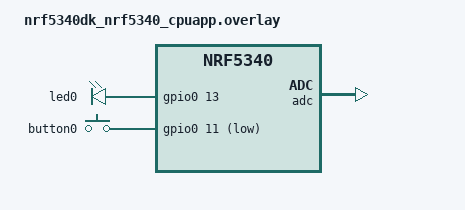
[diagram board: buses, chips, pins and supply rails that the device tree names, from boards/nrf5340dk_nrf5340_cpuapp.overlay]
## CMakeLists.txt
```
cmake_minimum_required(VERSION 3.13.1)
find_package(Zephyr REQUIRED HINTS $ENV{ZEPHYR_BASE})
project(fw_challenge)

target_sources(app PRIVATE
    src/main.c
    src/adc_sampler.c
    src/status_led.c
    src/buttons.c
    src/ble.c
)
target_include_directories(app PRIVATE include)
```

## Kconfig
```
menu "FW Challenge Options"

config APP_SAMPLE_INTERVAL_MS
    int "Sample interval (ms)"
    default 0
    help
      If non-zero, this Kconfig value takes precedence over the devicetree
      sample_interval_ms property. Use 0 to indicate "use devicetree/default".

config APP_ENABLE_BLE
    bool "Enable BLE support (build-time)"
    default y
    help
      If enabled, Bluetooth stack is built into the firmware. You can also
      disable Bluetooth with the overlay file 'overlay-no-ble.conf'.

config APP_LED_ACTIVE_LOW
    bool "Status LED active low"
    default n
    help
      Whether the status LED is active low. Defaults to n.

endmenu
```

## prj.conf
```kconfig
# Core
CONFIG_LOG=y
CONFIG_LOG_DEFAULT_LEVEL=3
CONFIG_SETTINGS=y
CONFIG_SETTINGS_NVS=y
CONFIG_NVS=y
CONFIG_FLASH=y
CONFIG_SYSTEM_WORKQUEUE=y
CONFIG_GPIO=y
CONFIG_ADC=y
CONFIG_PM=y
CONFIG_DEVICE_POWER_MANAGEMENT=y
CONFIG_MAIN_STACK_SIZE=2048

# Bluetooth (can be turned off with overlay-no-ble.conf)
CONFIG_BT=y
CONFIG_BT_PERIPHERAL=y
CONFIG_BT_DEVICE_NAME="FW-CHALLENGE"
CONFIG_BT_GATT_SERVICE_CHANGED=n
CONFIG_BT_MAX_CONN=1

# Enable ztest
CONFIG_ZTEST=y
```

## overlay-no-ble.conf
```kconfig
# Disable Bluetooth for builds that don't need it
CONFIG_BT=n
CONFIG_BT_PERIPHERAL=n
```

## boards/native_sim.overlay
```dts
/ {
    aliases {
        led-status = &led0;
        btn-user = &button0;
        adc0 = &adc_emul_0;
    };

    app {
        compatible = "app,config";
        sample-interval-ms = <1000>;
        voltage-threshold-mv = <3300>;
        enable-ble;
    };
};

/ {
    led0: led_0 {
        compatible = "gpio-leds";
        gpios = <&gpio0 13 GPIO_ACTIVE_HIGH>;
        label = "led0";
    };

    button0: button_0 {
        compatible = "gpio-keys";
        gpios = <&gpio0 11 GPIO_ACTIVE_LOW>;
        label = "button0";
        debounce-interval = <10>;
    };

    adc_emul_0: adc_emul_0 {
        compatible = "adc-emul";
        label = "ADC_EMUL_0";
        emul-type = "fixed";
        mv = <3700>;
    };
```

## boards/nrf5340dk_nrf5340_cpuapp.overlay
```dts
/ {
    aliases {
        led-status = &led0;
        btn-user = &button0;
        adc0 = &adc;
    };

    app {
        compatible = "app,config";
        sample-interval-ms = <1000>;
        voltage-threshold-mv = <3300>;
        enable-ble;
    };
};

&led0 {
    gpios = <&gpio0 13 GPIO_ACTIVE_HIGH>;
};

&button0 {
    gpios = <&gpio0 11 GPIO_ACTIVE_LOW>;
    debounce-interval = <10>;
    interrupts = <11 IRQ_TYPE_EDGE_TO_ACTIVE>;
};

&adc {
    status = "okay";
};
```

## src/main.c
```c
#include <zephyr.h>
#include <logging/log.h>
LOG_MODULE_REGISTER(app, LOG_LEVEL_INF);

#include "app_config.h"
#include "app_events.h"

#include <settings/settings.h>

/* Submodules */
extern int adc_sampler_init(uint32_t interval_ms);
extern void adc_sampler_start(void);
extern void adc_sampler_stop(void);
extern int status_led_init(bool active_low);
extern void status_led_set_state(int state);
extern int buttons_init(void);
extern int ble_init(void);

static void settings_set_cb(const char *name, size_t len, settings_read_cb read_cb, void *cb_arg);

static struct settings_handler app_sh = {
    .name = "app",
    .h_set = settings_set_cb,
};

static void settings_set_cb(const char *name, size_t len, settings_read_cb read_cb, void *cb_arg)
{
    /* implemented in adc_sampler.c via settings registration wrapper */
    /* Intentionally left blank here; the real handler is in adc_sampler */
}

void main(void)
{
    LOG_INF("FW Challenge booting");

    /* Settings subsystem (NVS backend) */
    settings_subsys_init();
    settings_load();
    settings_register(&app_sh);

    /* initialize modules */
    status_led_init(IS_ENABLED(CONFIG_APP_LED_ACTIVE_LOW));
    status_led_set_state(APP_STATE_IDLE);

#if CONFIG_APP_ENABLE_BLE
    if (ble_init() == 0) {
        LOG_INF("BLE initialized");
    } else {
        LOG_ERR("BLE failed to init");
    }
#else
    LOG_INF("BLE disabled by Kconfig/overlay");
#endif

    if (adc_sampler_init(app_sample_interval_ms()) == 0) {
        adc_sampler_start();
    } else {
        LOG_ERR("ADC sampler init failed");
        status_led_set_state(APP_STATE_ERROR);
    }

    buttons_init();

    LOG_INF("App started; sample interval: %u ms", app_sample_interval_ms());
}
```

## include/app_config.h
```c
#ifndef APP_CONFIG_H
#define APP_CONFIG_H

#include <zephyr/device.h>
#include <devicetree.h>

/* Devicetree / Kconfig precedence.
 * Policy used in this project:
 * - If Kconfig value APP_SAMPLE_INTERVAL_MS > 0 -> Kconfig takes precedence.
 * - Else use the devicetree value (DT_PATH(app) property sample_interval_ms).
 * - Else use compile-time hard-coded fallback.
 */

#ifdef CONFIG_APP_SAMPLE_INTERVAL_MS
#define KCONFIG_SAMPLE_INTERVAL_MS CONFIG_APP_SAMPLE_INTERVAL_MS
#else
#define KCONFIG_SAMPLE_INTERVAL_MS 0
#endif

/* devicetree defaults */
#if DT_NODE_HAS_PROP(DT_PATH(app), sample_interval_ms)
#define DT_SAMPLE_INTERVAL_MS DT_PROP(DT_PATH(app), sample_interval_ms)
#else
#define DT_SAMPLE_INTERVAL_MS 1000
#endif

static inline uint32_t app_sample_interval_ms(void)
{
#if KCONFIG_SAMPLE_INTERVAL_MS > 0
    return KCONFIG_SAMPLE_INTERVAL_MS;
#else
    return DT_SAMPLE_INTERVAL_MS;
#endif
}

#endif /* APP_CONFIG_H */
```

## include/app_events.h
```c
#ifndef APP_EVENTS_H
#define APP_EVENTS_H

#include <stdint.h>

enum app_state {
    APP_STATE_IDLE = 0,
    APP_STATE_SAMPLING,
    APP_STATE_ERROR,
};

#endif /* APP_EVENTS_H */
```

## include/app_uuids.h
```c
#ifndef APP_UUIDS_H
#define APP_UUIDS_H

#include <zephyr/types.h>

/* 128-bit base UUID for the app service: change to your own */
#define BT_UUID_APP_SERVICE_VAL \
    BT_UUID_128_ENCODE(0x12345678, 0x1234, 0x5678, 0x9abc, 0xdef012345678)

#endif /* APP_UUIDS_H */
```

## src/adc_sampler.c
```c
#include <zephyr.h>
#include <logging/log.h>
LOG_MODULE_REGISTER(adc_sampler, LOG_LEVEL_DBG);

#include <device.h>
#include <drivers/adc.h>
#include <pm/device.h>
#include <settings/settings.h>
#include <sys/byteorder.h>

#include "app_events.h"

/* sample_count persisted via settings: key "app/sample_count" */
static uint32_t sample_count = 0;
static const char *settings_key = "app/sample_count";

static int settings_set(const char *name, size_t len, settings_read_cb read_cb, void *cb_arg)
{
    if (!strcmp(name, "sample_count")) {
        if (len != sizeof(sample_count)) {
            return -EINVAL;
        }
        if (read_cb(cb_arg, &sample_count, len) == len) {
            LOG_INF("Restored sample_count=%u from settings", sample_count);
            return 0;
        }
        return -EIO;
    }
    return -ENOENT;
}

static struct settings_handler sh = {
    .name = "app",
    .h_set = settings_set,
};

/* ADC device (using devicetree alias 'adc0') */
#define ADC_DEVICE_NODE DT_ALIAS(adc0)

#if DT_NODE_HAS_STATUS(ADC_DEVICE_NODE, okay)
#define ADC_LABEL DT_LABEL(ADC_DEVICE_NODE)
#else
#define ADC_LABEL NULL
#endif

static const struct device *adc_dev = NULL;
static struct k_work_delayable sample_work;
static uint32_t sample_interval_ms = 1000;
static int current_state = APP_STATE_IDLE;

/* Forwarding function for BLE notification (implemented in ble.c) */
extern void ble_notify_voltage(uint32_t mv);

static void save_sample_count(void)
{
    int rc = settings_save_one(settings_key, &sample_count, sizeof(sample_count));
    if (rc) {
        LOG_ERR("settings_save_one failed: %d", rc);
    } else {
        LOG_DBG("Saved sample_count=%u", sample_count);
    }
}

static int adc_read_mv(uint32_t *mv_out)
{
    if (!adc_dev) {
        return -ENODEV;
    }

    /* Example: use ADC emulator which provides property "mv".
     * Here we try to read via a single-shot ADC channel for demo purposes.
     * This code may need platform-specific tweaks (channel setup, resolution).
     */

    const struct device *dev = adc_dev;

    /* If device power management is enabled, optionally resume */
    pm_device_action_run(dev, PM_DEVICE_ACTION_RESUME);

    /* For simulator/emulator, fetch a property as a fallback */
#ifdef CONFIG_ADC
    /* Try to use emulator property via DT (if present) */
#if DT_NODE_HAS_PROP(ADC_DEVICE_NODE, mv)
    *mv_out = DT_PROP(ADC_DEVICE_NODE, mv);
    pm_device_action_run(dev, PM_DEVICE_ACTION_SUSPEND);
    return 0;
#else
    /* Generic ADC read pathway - platform specific; return error to indicate not-implemented */
    pm_device_action_run(dev, PM_DEVICE_ACTION_SUSPEND);
    return -ENOTSUP;
#endif
#else
    return -ENODEV;
#endif
}

static void sample_work_handler(struct k_work *work)
{
    ARG_UNUSED(work);
    uint32_t mv = 0;
    current_state = APP_STATE_SAMPLING;
    /* update LED state via status_led module */
    extern void status_led_set_state(int state);
    status_led_set_state(current_state);

    int rc = adc_read_mv(&mv);
    if (rc == 0) {
        sample_count++;
        LOG_INF("ADC sample: %u mV (count=%u)", mv, sample_count);
        save_sample_count();
        /* notify over BLE if connected + enabled */
        ble_notify_voltage(mv);
        current_state = APP_STATE_IDLE;
        status_led_set_state(current_state);
    } else {
        LOG_ERR("ADC read failed: %d", rc);
        current_state = APP_STATE_ERROR;
        status_led_set_state(current_state);
    }

    /* re-schedule */
    k_work_reschedule(&sample_work, K_MSEC(sample_interval_ms));
}

int adc_sampler_init(uint32_t interval_ms)
{
    sample_interval_ms = interval_ms;
    /* init settings handler */
    settings_register(&sh);

    if (ADC_LABEL == NULL) {
        LOG_WRN("No ADC device alias found in DT (using emulator fallback where available).");
    } else {
        adc_dev = device_get_binding(ADC_LABEL);
        if (!adc_dev) {
            LOG_WRN("ADC device '%s' not ready; continuing (emulator fallback)", ADC_LABEL);
        }
    }

    k_work_init_delayable(&sample_work, sample_work_handler);
    return 0;
}

void adc_sampler_start(void)
{
    k_work_reschedule(&sample_work, K_MSEC(sample_interval_ms));
}

void adc_sampler_stop(void)
{
    k_work_cancel_delayable(&sample_work);
}
```

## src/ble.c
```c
#include <zephyr.h>
#include <logging/log.h>
LOG_MODULE_REGISTER(ble, LOG_LEVEL_INF);

#include <bluetooth/bluetooth.h>
#include <bluetooth/hci.h>
#include <bluetooth/gatt.h>
#include <sys/byteorder.h>

#include "app_uuids.h"

/* UUIDs */
static struct bt_uuid_128 app_service_uuid = BT_UUID_INIT_128(
    0x78,0x56,0x34,0x12, 0x34,0x12, 0x78,0x56, 0x9a,0xbc, 0xde,0xf0,0x12,0x34,0x56,0x78
);

/* Local value storage */
static uint32_t last_voltage_mv = 0;
static uint32_t sample_interval_ms = 0;

/* CCC state */
static uint8_t ccc_cfg[BT_GATT_CCC_MAX];

/* Connection */
static struct bt_conn *current_conn;

/* Forward to allow adc sampler to call into BLE notify */
void ble_notify_voltage(uint32_t mv)
{
    last_voltage_mv = mv;
    if (current_conn && bt_gatt_is_subscribed(current_conn, &voltage_attr, BT_GATT_CCC_NOTIFY)) {
        uint8_t buf[4];
        sys_put_le32(mv, buf);
        bt_gatt_notify(current_conn, &voltage_attr, buf, sizeof(buf));
    }
}

/* Read handlers */
static ssize_t read_voltage(struct bt_conn *conn, const struct bt_gatt_attr *attr,
                void *buf, uint16_t len, uint16_t offset)
{
    uint8_t val[4];
    sys_put_le32(last_voltage_mv, val);
    return bt_gatt_attr_read(conn, attr, buf, len, offset, val, sizeof(val));
}

static ssize_t read_interval(struct bt_conn *conn, const struct bt_gatt_attr *attr,
                void *buf, uint16_t len, uint16_t offset)
{
    uint8_t val[4];
    sys_put_le32(sample_interval_ms, val);
    return bt_gatt_attr_read(conn, attr, buf, len, offset, val, sizeof(val));
}

/* CCC changed callback */
static void ccc_changed(const struct bt_gatt_attr *attr, uint16_t value)
{
    ARG_UNUSED(attr);
    LOG_INF("CCC changed: %u", value);
}

/* GATT attributes (service + characteristics) */
static struct bt_gatt_attr voltage_attr;

/* We'll build the GATT service dynamically in bt_ready callback */
static struct bt_gatt_attr attrs[8];

static ssize_t bt_connected(struct bt_conn *conn, uint8_t err)
{
    if (err) {
        LOG_ERR("Connection failed (err %u)", err);
    } else {
        LOG_INF("Connected");
        current_conn = bt_conn_ref(conn);
    }
    return 0;
}

static void bt_disconnected(struct bt_conn *conn, uint8_t reason)
{
    LOG_INF("Disconnected (reason %u)", reason);
    if (current_conn) {
        bt_conn_unref(current_conn);
        current_conn = NULL;
    }
}

static struct bt_conn_cb conn_callbacks = {
    .connected = bt_connected,
    .disconnected = bt_disconnected,
};

static const struct bt_data ad[] = {
    BT_DATA_BYTES(BT_DATA_FLAGS, (BT_LE_AD_GENERAL | BT_LE_AD_NO_BREDR)),
    BT_DATA(BT_DATA_NAME_COMPLETE, "FW-CHALLENGE", 12),
};

static void bt_ready(int err)
{
    if (err) {
        LOG_ERR("Bluetooth init failed: %d", err);
        return;
    }
    LOG_INF("Bluetooth initialized");
    bt_conn_cb_register(&conn_callbacks);

    /* create & register GATT service */
    /* For clarity we use the BT_GATT_SERVICE_DEFINE macro */

    BT_GATT_SERVICE_DEFINE(app_svc,
        BT_GATT_PRIMARY_SERVICE(&app_service_uuid),
        BT_GATT_CHARACTERISTIC(BT_UUID_DECLARE_128(
            0x78,0x56,0x34,0x12, 0x34,0x12, 0x78,0x56, 0x9a,0xbc, 0xde,0xf0,0x12,0x34,0x56,0x78),
            BT_GATT_CHRC_READ | BT_GATT_CHRC_NOTIFY,
            BT_GATT_PERM_READ,
            read_voltage, NULL, NULL),
        BT_GATT_CCC(ccc_changed, BT_GATT_PERM_READ | BT_GATT_PERM_WRITE),
        BT_GATT_CHARACTERISTIC(BT_UUID_DECLARE_128(
            0x78,0x56,0x34,0x12, 0x34,0x12, 0x78,0x56, 0x9a,0xbc, 0xde,0xf0,0x12,0x34,0x56,0x79),
            BT_GATT_CHRC_READ,
            BT_GATT_PERM_READ,
            read_interval, NULL, NULL),
    );
    /* advertising */
    bt_le_adv_start(BT_LE_ADV_CONN_NAME, ad, ARRAY_SIZE(ad), NULL, 0);
}

int ble_init(void)
{
    int rc = bt_enable(bt_ready);
    if (rc) {
        LOG_ERR("bt_enable returned %d", rc);
        return rc;
    }
    /* sample interval: read from app config */
#if defined(CONFIG_APP_SAMPLE_INTERVAL_MS) && (CONFIG_APP_SAMPLE_INTERVAL_MS > 0)
    sample_interval_ms = CONFIG_APP_SAMPLE_INTERVAL_MS;
#elif DT_NODE_HAS_PROP(DT_PATH(app), sample_interval_ms)
    sample_interval_ms = DT_PROP(DT_PATH(app), sample_interval_ms);
#else
    sample_interval_ms = 1000;
#endif
    return 0;
}
```

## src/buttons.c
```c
#include <zephyr.h>
#include <logging/log.h>
LOG_MODULE_REGISTER(buttons, LOG_LEVEL_DBG);

#include <device.h>
#include <drivers/gpio.h>
#include <devicetree.h>

/* Use alias btn-user */
#if DT_NODE_HAS_STATUS(DT_ALIAS(btn_user), okay)
#define BTN_NODE DT_ALIAS(btn_user)
#else
#define BTN_NODE DT_NODELABEL(button0)
#endif

static const struct device *btn_dev;
static struct gpio_callback btn_cb_data;
static struct k_work button_work;

extern void app_button_pressed(void);

/* deferred work to handle the button press logic (debounce + toggle) */
static void button_work_handler(struct k_work *work)
{
    app_button_pressed();
}

static void button_pressed_isr(const struct device *dev, struct gpio_callback *cb, uint32_t pins)
{
    ARG_UNUSED(dev);
    ARG_UNUSED(cb);
    ARG_UNUSED(pins);
    /* schedule deferred handling */
    k_work_submit(&button_work);
}

int buttons_init(void)
{
    k_work_init(&button_work, button_work_handler);

#if DT_NODE_HAS_STATUS(BTN_NODE, okay)
    const char *label = DT_LABEL(BTN_NODE);
    btn_dev = device_get_binding(label);
    if (!btn_dev) {
        btn_dev = device_get_binding(DT_LABEL(DT_NODELABEL(gpio0)));
    }
#else
    btn_dev = device_get_binding(DT_LABEL(DT_NODELABEL(gpio0)));
#endif
    if (!btn_dev) {
        return -ENODEV;
    }

    gpio_pin_configure(btn_dev, 11, GPIO_INPUT | GPIO_INT_EDGE_TO_ACTIVE | GPIO_PULL_UP);
    gpio_init_callback(&btn_cb_data, button_pressed_isr, BIT(11));
    gpio_add_callback(btn_dev, &btn_cb_data);
    gpio_pin_interrupt_configure(btn_dev, 11, GPIO_INT_EDGE_TO_ACTIVE);

    return 0;
}
```

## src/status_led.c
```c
#include <zephyr.h>
#include <logging/log.h>
LOG_MODULE_REGISTER(status_led, LOG_LEVEL_DBG);

#include <device.h>
#include <drivers/gpio.h>
#include <devicetree.h>

#include "app_events.h"

/* Use DT alias 'led-status' */
#ifdef DT_ALIAS(led_status)
#define LED_NODE DT_ALIAS(led_status)
#else
#define LED_NODE DT_NODELABEL(led0)
#endif

static const struct device *led_dev;
static gpio_pin_t led_pin = 13;
static bool led_active_low = false;

static int current_state = APP_STATE_IDLE;
static struct k_work_delayable led_worker;

static void led_update_once(struct k_work *work)
{
    ARG_UNUSED(work);
    /* Implement simple blink patterns depending on state */
    switch (current_state) {
    case APP_STATE_IDLE:
        gpio_pin_toggle(led_dev, led_pin);
        k_work_reschedule(&led_worker, K_MSEC(1000));
        break;
    case APP_STATE_SAMPLING:
        /* Two quick blinks */
        gpio_pin_set(led_dev, led_pin, !led_active_low);
        k_msleep(80);
        gpio_pin_set(led_dev, led_pin, led_active_low);
        k_msleep(80);
        gpio_pin_set(led_dev, led_pin, !led_active_low);
        k_msleep(80);
        gpio_pin_set(led_dev, led_pin, led_active_low);
        k_work_reschedule(&led_worker, K_MSEC(500));
        break;
    case APP_STATE_ERROR:
        gpio_pin_toggle(led_dev, led_pin);
        k_work_reschedule(&led_worker, K_MSEC(200));
        break;
    default:
        k_work_reschedule(&led_worker, K_MSEC(1000));
    }
}

int status_led_init(bool active_low)
{
    led_active_low = active_low;

    /* Attempt to bind to a gpio device from DT alias; fallback to gpio0 */
#if DT_NODE_HAS_STATUS(LED_NODE, okay)
    const char *label = DT_LABEL(LED_NODE);
    led_dev = device_get_binding(label);
    if (!led_dev) {
        led_dev = device_get_binding(DT_LABEL(DT_NODELABEL(gpio0)));
    }
#else
    led_dev = device_get_binding(DT_LABEL(DT_NODELABEL(gpio0)));
#endif
    if (!led_dev) {
        LOG_ERR("No GPIO controller found for LED");
        return -ENODEV;
    }

    /* Use a default pin (board overlay should set the proper pin via DT in practice) */
    gpio_pin_configure(led_dev, led_pin, GPIO_OUTPUT_ACTIVE | (led_active_low ? GPIO_ACTIVE_LOW : GPIO_ACTIVE_HIGH));
    k_work_init_delayable(&led_worker, led_update_once);
    /* start blinking */
    k_work_reschedule(&led_worker, K_MSEC(1000));
    return 0;
}

void status_led_set_state(int state)
{
    current_state = state;
    /* trigger immediate update */
    k_work_reschedule(&led_worker, K_NO_WAIT);
}
```
